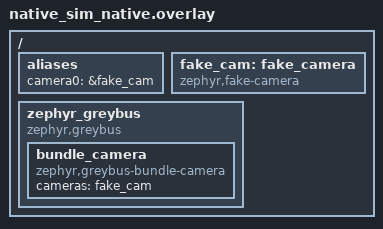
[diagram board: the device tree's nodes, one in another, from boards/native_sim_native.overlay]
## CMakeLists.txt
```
cmake_minimum_required(VERSION 3.20.0)
find_package(Zephyr REQUIRED HINTS $ENV{ZEPHYR_BASE})

set(DTS_ROOT ${CMAKE_CURRENT_SOURCE_DIR})
project(fake_camera_test)

#absolute path
get_filename_component(GB_ROOT ${CMAKE_CURRENT_SOURCE_DIR}/../../../.. ABSOLUTE)

#compiling both the test and driver
target_sources(app PRIVATE 
    src/main.c
    ${GB_ROOT}/drivers/video/fake_camera.c
)
```

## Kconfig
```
source "Kconfig.zephyr"
rsource "../../../../drivers/video/Kconfig"
```

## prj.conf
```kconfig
CONFIG_ZTEST=y
CONFIG_VIDEO=y
CONFIG_FAKE_CAMERA=y
CONFIG_LOG=y
CONFIG_GREYBUS=y
CONFIG_GREYBUS_LOG_LEVEL_DBG=y
CONFIG_VIDEO_BUFFER_POOL_HEAP_SIZE=4096
CONFIG_VIDEO_BUFFER_POOL_NUM_MAX=4
CONFIG_GREYBUS_CAMERA=y
```

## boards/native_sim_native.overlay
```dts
/ {
    aliases {
        camera0 = &fake_cam;
    };

    fake_cam: fake_camera {
        compatible = "zephyr,fake-camera";
        status = "okay";
    };

    zephyr_greybus {
        compatible = "zephyr,greybus";
        status = "okay";
        
        bundle_camera: bundle_camera {
            compatible = "zephyr,greybus-bundle-camera";
            status = "okay";
            /* This is the magic property our macro loops over! */
            cameras = <&fake_cam>; 
        };
    };
};
```

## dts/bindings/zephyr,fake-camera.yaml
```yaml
description: Fake Camera Driver for Simulation
compatible: "zephyr,fake-camera"
include: base.yaml
```

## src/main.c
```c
#include <zephyr/ztest.h>
#include <zephyr/drivers/video.h>
#include <zephyr/device.h>

#define VBUF_SIZE 1024

static struct video_buffer *vbuf;

ZTEST(camera_suite, test_camera_device_ready)
{
	const struct device *dev = DEVICE_DT_GET(DT_ALIAS(camera0));
	zassert_true(device_is_ready(dev), "Camera device not ready");
}

ZTEST(camera_suite, test_camera_frame_capture)
{
	const struct device *dev = DEVICE_DT_GET(DT_ALIAS(camera0));
	struct video_buffer *rx_buf;
	int err;

	vbuf = video_buffer_alloc(VBUF_SIZE, K_NO_WAIT);
	zassert_not_null(vbuf, "Failed to allocate video buffer");

	vbuf->type = VIDEO_BUF_TYPE_OUTPUT;

	video_enqueue(dev, vbuf);
	video_stream_start(dev, VIDEO_BUF_TYPE_OUTPUT);

	err = video_dequeue(dev, &rx_buf, K_MSEC(500));
	zassert_equal(err, 0, "Failed to dequeue (err: %d)", err);
	zassert_equal(rx_buf->bytesused, VBUF_SIZE, "Wrong frame size");

	video_stream_stop(dev, VIDEO_BUF_TYPE_OUTPUT);
	video_buffer_release(vbuf);
}

ZTEST_SUITE(camera_suite, NULL, NULL, NULL, NULL, NULL);
```

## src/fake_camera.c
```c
#define DT_DRV_COMPAT zephyr_fake_camera

#include <zephyr/device.h>
#include <zephyr/drivers/video.h>
#include <zephyr/logging/log.h>
#include <zephyr/kernel.h>
#include <string.h>

LOG_MODULE_REGISTER(fake_cam, LOG_LEVEL_INF);

struct cam_data {
	struct video_format fmt;
	struct k_fifo in_queue;
	struct k_fifo out_queue;
	struct k_timer frame_timer;
};
// there is an empty buffer queue and also a full buffer queue

static void frame_timer_handler(struct k_timer *timer)
{
	struct cam_data *data = CONTAINER_OF(timer, struct cam_data, frame_timer);
	struct video_buffer *vbuf;

	vbuf = k_fifo_get(&data->in_queue, K_NO_WAIT);
	if (vbuf != NULL) {
		memset(vbuf->buffer, 0xAA, vbuf->size);
		vbuf->bytesused = vbuf->size;
		vbuf->timestamp = k_uptime_get_32();

		k_fifo_put(&data->out_queue, vbuf);
		LOG_INF("Generated dummy frame (%d bytes)", vbuf->bytesused);
	}
}

// to fill the empty buffer
static int cam_enqueue(const struct device *dev, struct video_buffer *vbuf)
{
	struct cam_data *data = dev->data;
	k_fifo_put(&data->in_queue, vbuf);
	return 0;
}

// to give out the filled buffer
static int cam_dequeue(const struct device *dev, struct video_buffer **vbuf, k_timeout_t timeout)
{
	struct cam_data *data = dev->data;
	*vbuf = k_fifo_get(&data->out_queue, timeout);
	if (!(*vbuf)) {
		return -EAGAIN;
	}
	return 0;
}

static int cam_set_stream(const struct device *dev, bool enable, enum video_buf_type type)
{
	struct cam_data *data = dev->data;
	if (enable) {
		LOG_INF("Stream started at 10fps");
		k_timer_start(&data->frame_timer, K_MSEC(100), K_MSEC(100));
	} else {
		LOG_INF("Stream stopped");
		k_timer_stop(&data->frame_timer);
	}
	return 0;
}

static int cam_get_caps(const struct device *dev, struct video_caps *caps)
{
	return 0;
}
static int cam_set_format(const struct device *dev, struct video_format *fmt)
{
	return 0;
}

static const struct video_driver_api cam_driver_api = {
	.set_format = cam_set_format,
	.get_caps = cam_get_caps,
	.set_stream = cam_set_stream,
	.enqueue = cam_enqueue,
	.dequeue = cam_dequeue,
};

static int cam_init(const struct device *dev)
{
	struct cam_data *data = dev->data;
	k_fifo_init(&data->in_queue);
	k_fifo_init(&data->out_queue);
	k_timer_init(&data->frame_timer, frame_timer_handler, NULL);

	LOG_INF("INIT: camera driver initialised.");
	return 0;
}

static struct cam_data cam_data;

DEVICE_DT_INST_DEFINE(0, cam_init, NULL, &cam_data, NULL, POST_KERNEL, CONFIG_VIDEO_INIT_PRIORITY,
		      &cam_driver_api);
```
